# phy_pcs_cmn_registers: IP-XACT component
VLNV cadence:cdns_lib:phy_pcs_cmn_registers:1685-2009

## Address spaces and blocks
sd3101_t4_registers.sd3101_phy_registers: base 0x30000, range 0x3ff, width 32

## Registers
Registers are 32-bit, read-write, reset 0x0 unless marked. A register's access mark holds for its fields unless they carry their own. Offsets are from the block's base; lines under a group give offsets from that group; [hi:lo] are bit positions; {n}, {i} and the like mark numbered series; 'fields as' and 'values as' point back to an identical list; <NAME> marks a mode.

## sd3101_t4_registers.sd3101_phy_registers
Base 0x00030000
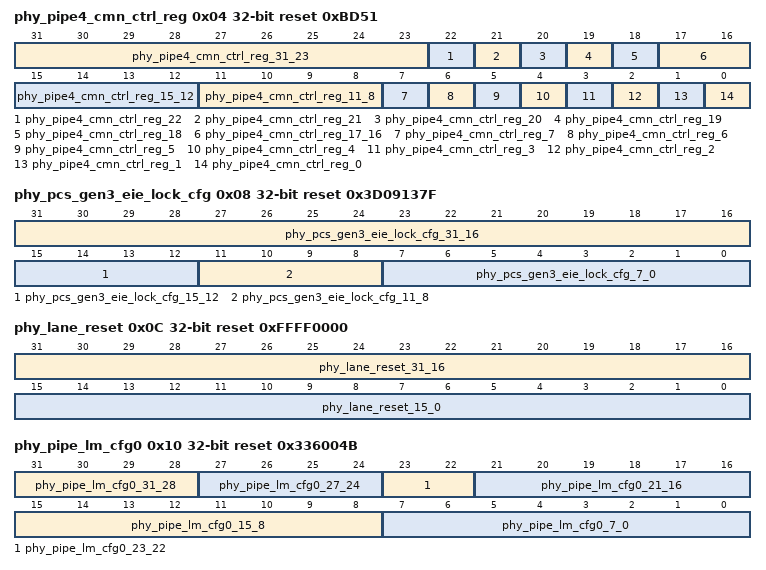
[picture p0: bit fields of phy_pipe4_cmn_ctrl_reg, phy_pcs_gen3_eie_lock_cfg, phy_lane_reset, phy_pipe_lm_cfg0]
0x04 phy_pipe4_cmn_ctrl_reg reset 0xBD51 — PIPE4 common control register
  [31:23] phy_pipe4_cmn_ctrl_reg_31_23 ro — RSVD3
  [22] phy_pipe4_cmn_ctrl_reg_22 — 128B_EIOS_CLR_CAL
  [21] phy_pipe4_cmn_ctrl_reg_21 — 128B_IGNORE_SIGDET
  [20] phy_pipe4_cmn_ctrl_reg_20 — 8B10B_IGNORE_SIGDET
  [19] phy_pipe4_cmn_ctrl_reg_19 — EIOS_CYC_ERR_MSK
  [18] phy_pipe4_cmn_ctrl_reg_18 — EIOS_CLR_CAL
  [17:16] phy_pipe4_cmn_ctrl_reg_17_16 — SIGDET_DEL
  [15:12] phy_pipe4_cmn_ctrl_reg_15_12 — USB_SS_LFPS_STRETCH
  [11:8] phy_pipe4_cmn_ctrl_reg_11_8 — USB_SSPLUS_LFPS_STRETCH
  [7] phy_pipe4_cmn_ctrl_reg_7 ro — RSVD2
  [6] phy_pipe4_cmn_ctrl_reg_6 — TX_ELEC_IDLE_PRE_REL
  [5] phy_pipe4_cmn_ctrl_reg_5 ro — RSVD1
  [4] phy_pipe4_cmn_ctrl_reg_4 — CAL_REALIGN
  [3] phy_pipe4_cmn_ctrl_reg_3 — USB_ERR_COR_DISABLE
  [2] phy_pipe4_cmn_ctrl_reg_2 — USB_PIPE3_SKIP_COMP_EN
  [1] phy_pipe4_cmn_ctrl_reg_1 — USB_LPBKSLV_EC_DISABLE
  [0] phy_pipe4_cmn_ctrl_reg_0 — USB_EB_REALIGN_EN
0x08 phy_pcs_gen3_eie_lock_cfg reset 0x3D09137F — PHY PCS Gen3 EIE lock configuration register
  [31:16] phy_pcs_gen3_eie_lock_cfg_31_16 — RCV_DET_INH
  [15:12] phy_pcs_gen3_eie_lock_cfg_15_12 — EIE_FAST_LOCK_CNT
  [11:8] phy_pcs_gen3_eie_lock_cfg_11_8 — EIE_LOCK_CNT
  [7:0] phy_pcs_gen3_eie_lock_cfg_7_0 — EIE_FULL_LOCK_CNT
0x0C phy_lane_reset reset 0xFFFF0000
  [31:16] phy_lane_reset_31_16 — CDB_RST
  [15:0] phy_lane_reset_15_0 ro — RSVD
0x10 phy_pipe_lm_cfg0 reset 0x336004B — PIPE lane margining configuration 0 register
  [31:28] phy_pipe_lm_cfg0_31_28 ro — RSVD2
  [27:24] phy_pipe_lm_cfg0_27_24 — WAIT_TIME
  [23:22] phy_pipe_lm_cfg0_23_22 ro — RSVD1
  [21:16] phy_pipe_lm_cfg0_21_16 — SMPL_CNT
  [15:8] phy_pipe_lm_cfg0_15_8 ro — RSVD0
  [7:0] phy_pipe_lm_cfg0_7_0 — CFG
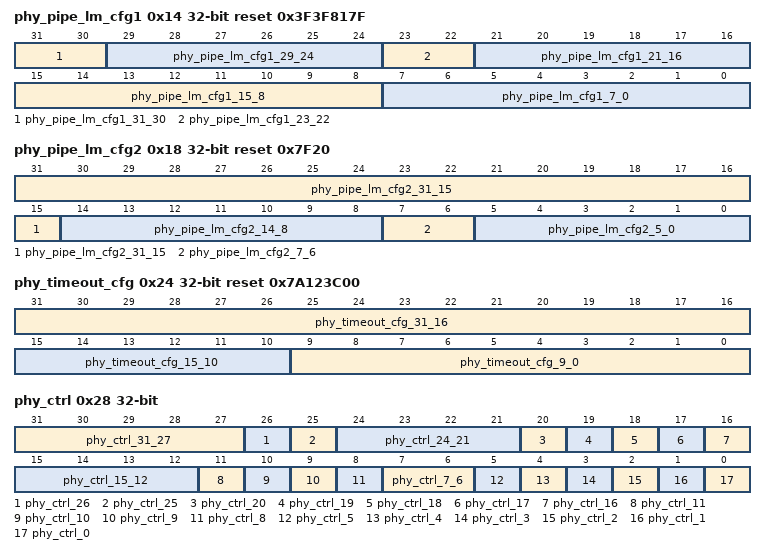
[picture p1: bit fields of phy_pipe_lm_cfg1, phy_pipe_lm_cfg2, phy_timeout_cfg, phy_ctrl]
0x14 phy_pipe_lm_cfg1 reset 0x3F3F817F — PIPE lane margining configuration 1 register
  [31:30] phy_pipe_lm_cfg1_31_30 ro — RSVD1
  [29:24] phy_pipe_lm_cfg1_29_24 — ERR_CNT_THR
  [23:22] phy_pipe_lm_cfg1_23_22 ro — RSVD0
  [21:16] phy_pipe_lm_cfg1_21_16 — ERR_CNT_MAX
  [15:8] phy_pipe_lm_cfg1_15_8 — SMP_CNT_THR
  [7:0] phy_pipe_lm_cfg1_7_0 — SMP_CNT_MAX
0x18 phy_pipe_lm_cfg2 reset 0x7F20 — PIPE lane margining configuration 2 register
  [31:15] phy_pipe_lm_cfg2_31_15 ro — RSVD1
  [14:8] phy_pipe_lm_cfg2_14_8 — VOLT_OFFSET
  [7:6] phy_pipe_lm_cfg2_7_6 ro — RSVD0
  [5:0] phy_pipe_lm_cfg2_5_0 — TIME_OFFSET
0x24 phy_timeout_cfg reset 0x7A123C00 — PHY timeout configuration register
  [31:16] phy_timeout_cfg_31_16 — ST_CHG_TO
  [15:10] phy_timeout_cfg_15_10 — L1_X_EXIT_FAST_CNT
  [9:0] phy_timeout_cfg_9_0 ro — RSVD
0x28 phy_ctrl — PHY common control and status register
  [31:27] phy_ctrl_31_27 ro — RSVD
  [26] phy_ctrl_26 ro — typec_conn_dir_cdb
  [25] phy_ctrl_25 ro — RSVD
  [24:21] phy_ctrl_24_21 ro — phy_mode_cdb
  [20] phy_ctrl_20 ro — PIPE4_RESET_N
  [19] phy_ctrl_19 ro — PIPE7_RESET_N
  [18] phy_ctrl_18 ro — DP_RESET_N
  [17] phy_ctrl_17 write-1-clears — APB_MSTR_PERR
  [16] phy_ctrl_16 write-1-clears — CDB_PERROR_PHY
  [15:12] phy_ctrl_15_12 ro — RSVD4
  [11] phy_ctrl_11 — PERR_FLAG
  [10] phy_ctrl_10 ro — RSVD3
  [9] phy_ctrl_9 ro — MAX_PCLK_ACK
  [8] phy_ctrl_8 ro — MAX_PCLK_REQ
  [7:6] phy_ctrl_7_6 ro — RSVD3
  [5] phy_ctrl_5 write-1-clears — PLL_OK
  [4] phy_ctrl_4 ro — PIPE7_PLL0_EN
  [3] phy_ctrl_3 ro — RSVD2
  [2] phy_ctrl_2 ro — RSVD1
  [1] phy_ctrl_1 ro — PHY_RESET_N
  [0] phy_ctrl_0 write-1-clears — UC_INIT_COMPLETE
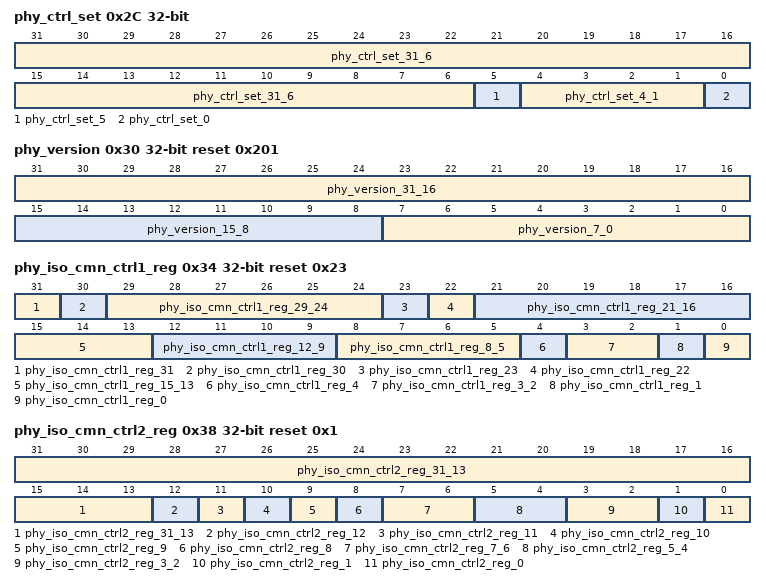
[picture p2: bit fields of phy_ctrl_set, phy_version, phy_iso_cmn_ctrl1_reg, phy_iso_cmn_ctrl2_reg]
0x2C phy_ctrl_set — PHY control and status set register
  [31:6] phy_ctrl_set_31_6 ro — RSVD
  [5] phy_ctrl_set_5 write-1-sets — SET5
  [4:1] phy_ctrl_set_4_1 ro — RSVD
  [0] phy_ctrl_set_0 write-1-sets — SET0
0x30 phy_version reset 0x201
  [31:16] phy_version_31_16 ro — RSVD
  [15:8] phy_version_15_8 ro — MAJOR_REV
  [7:0] phy_version_7_0 ro — MINOR_REV
0x34 phy_iso_cmn_ctrl1_reg reset 0x23 — PHY ISO common control 1 register
  [31] phy_iso_cmn_ctrl1_reg_31 ro — PMA_XCVR_PLLCLK_EN_ACK
  [30] phy_iso_cmn_ctrl1_reg_30 — tx_lfps_mode
  [29:24] phy_iso_cmn_ctrl1_reg_29_24 ro — xcvr_power_state_ack
  [23] phy_iso_cmn_ctrl1_reg_23 — PLLCLK_EN
  [22] phy_iso_cmn_ctrl1_reg_22 — tx_lfps_en
  [21:16] phy_iso_cmn_ctrl1_reg_21_16 — ISO_CMN_CTRL1_BITS
  [15:13] phy_iso_cmn_ctrl1_reg_15_13 — xcvr_data_width_ln
  [12:9] phy_iso_cmn_ctrl1_reg_12_9 ro — RSVD
  [8:5] phy_iso_cmn_ctrl1_reg_8_5 — PHY_MODE
  [4] phy_iso_cmn_ctrl1_reg_4 — TYPEC_CONN_DIR
  [3:2] phy_iso_cmn_ctrl1_reg_3_2 ro — RSVD
  [1] phy_iso_cmn_ctrl1_reg_1 — DP_RST_N
  [0] phy_iso_cmn_ctrl1_reg_0 — PHY_RST_N
0x38 phy_iso_cmn_ctrl2_reg reset 0x1 — PHY ISO common control 2 register
  [31:13] phy_iso_cmn_ctrl2_reg_31_13 ro — RSVD
  [12] phy_iso_cmn_ctrl2_reg_12 — PIPE4_EB_MODE
  [11] phy_iso_cmn_ctrl2_reg_11 ro — RSVD
  [10] phy_iso_cmn_ctrl2_reg_10 — PIPE4_32BIT_SEL
  [9] phy_iso_cmn_ctrl2_reg_9 ro — RSVD
  [8] phy_iso_cmn_ctrl2_reg_8 — PIPE4_RATE
  [7:6] phy_iso_cmn_ctrl2_reg_7_6 ro — RSVD
  [5:4] phy_iso_cmn_ctrl2_reg_5_4 — PIPE4_PWRDWN
  [3:2] phy_iso_cmn_ctrl2_reg_3_2 ro — RSVD
  [1] phy_iso_cmn_ctrl2_reg_1 ro — RSVD
  [0] phy_iso_cmn_ctrl2_reg_0 — PIPE4_RST_N
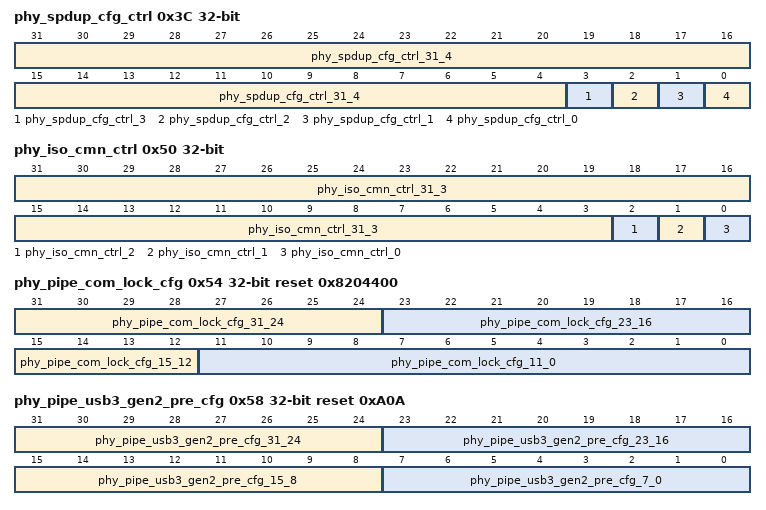
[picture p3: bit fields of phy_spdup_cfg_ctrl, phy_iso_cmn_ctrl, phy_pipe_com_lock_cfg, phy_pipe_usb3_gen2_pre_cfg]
0x3C phy_spdup_cfg_ctrl — PHY speedup configuration and control register
  [31:4] phy_spdup_cfg_ctrl_31_4 ro — RSVD1
  [3] phy_spdup_cfg_ctrl_3 ro — SPDUP_CMPL
  [2] phy_spdup_cfg_ctrl_2 — SPDUP_STALL
  [1] phy_spdup_cfg_ctrl_1 — SPDUP_EN
  [0] phy_spdup_cfg_ctrl_0 ro — RSVD0
0x50 phy_iso_cmn_ctrl — PHY common control signal isolation register
  [31:3] phy_iso_cmn_ctrl_31_3 ro — RSVD
  [2] phy_iso_cmn_ctrl_2 — PLL_EN
  [1] phy_iso_cmn_ctrl_1 — CLK_MAX_REQ
  [0] phy_iso_cmn_ctrl_0 ro — RSVD0
0x54 phy_pipe_com_lock_cfg reset 0x8204400 — PHY PIPE common lock configuration register
  [31:24] phy_pipe_com_lock_cfg_31_24 — COM_FAST_LOCK_CNT
  [23:16] phy_pipe_com_lock_cfg_23_16 — COM_LOCK_CNT
  [15:12] phy_pipe_com_lock_cfg_15_12 — CAL_UNLOCK_CNT
  [11:0] phy_pipe_com_lock_cfg_11_0 — COM_FULL_LOCK_CNT
0x58 phy_pipe_usb3_gen2_pre_cfg reset 0xA0A — PHY USB3 Gen 2 pre-shoot configuration register
  [31:24] phy_pipe_usb3_gen2_pre_cfg_31_24 — COM_FAST_LOCK_CNT
  [23:16] phy_pipe_usb3_gen2_pre_cfg_23_16 — COM_LOCK_CNT
  [15:8] phy_pipe_usb3_gen2_pre_cfg_15_8 — CAL_UNLOCK_CNT
  [7:0] phy_pipe_usb3_gen2_pre_cfg_7_0 — COM_FULL_LOCK_CNT
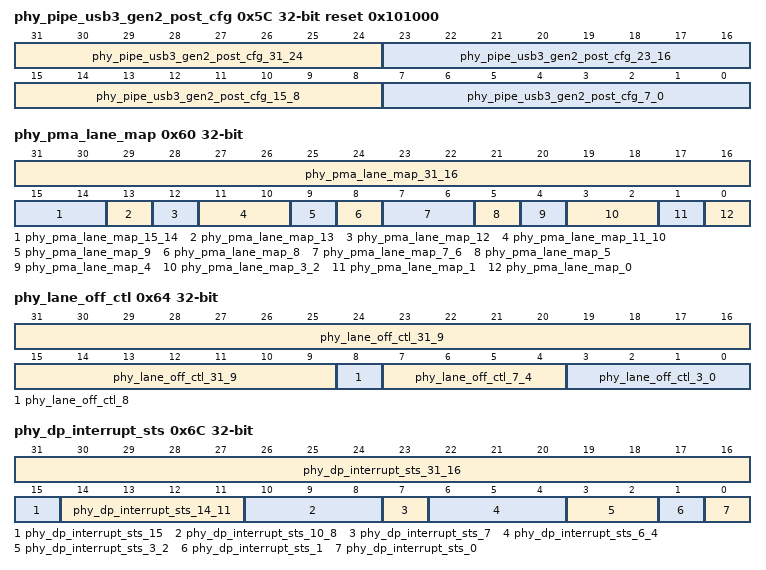
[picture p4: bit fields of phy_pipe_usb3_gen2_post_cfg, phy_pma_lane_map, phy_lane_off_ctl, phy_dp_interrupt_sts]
0x5C phy_pipe_usb3_gen2_post_cfg reset 0x101000 — PHY USB3 Gen 2 pre-shoot configuration register
  [31:24] phy_pipe_usb3_gen2_post_cfg_31_24 — COM_FAST_LOCK_CNT
  [23:16] phy_pipe_usb3_gen2_post_cfg_23_16 — COM_LOCK_CNT
  [15:8] phy_pipe_usb3_gen2_post_cfg_15_8 — CAL_UNLOCK_CNT
  [7:0] phy_pipe_usb3_gen2_post_cfg_7_0 — COM_FULL_LOCK_CNT
0x60 phy_pma_lane_map — PHY/PMA Lane Mapping Register
  [31:16] phy_pma_lane_map_31_16 ro — RSVD
  [15:14] phy_pma_lane_map_15_14 — PMA_L3_MAP
  [13] phy_pma_lane_map_13 ro — RSVD
  [12] phy_pma_lane_map_12 — PMA_L3_SEL
  [11:10] phy_pma_lane_map_11_10 — PMA_L2_MAP
  [9] phy_pma_lane_map_9 ro — RSVD
  [8] phy_pma_lane_map_8 — PMA_L2_SEL
  [7:6] phy_pma_lane_map_7_6 — PMA_L1_MAP
  [5] phy_pma_lane_map_5 ro — RSVD
  [4] phy_pma_lane_map_4 — PMA_L1_SEL
  [3:2] phy_pma_lane_map_3_2 — PMA_L0_MAP
  [1] phy_pma_lane_map_1 ro — RSVD
  [0] phy_pma_lane_map_0 — PMA_L0_SEL
0x64 phy_lane_off_ctl — PHY Lane Off control register
  [31:9] phy_lane_off_ctl_31_9 ro — RSVD
  [8] phy_lane_off_ctl_8 — USB_LANE_DISABLE
  [7:4] phy_lane_off_ctl_7_4 ro — RSVD
  [3:0] phy_lane_off_ctl_3_0 — DP_LANE_DISABLE
0x6C phy_dp_interrupt_sts — PHY DP state change status register
  [31:16] phy_dp_interrupt_sts_31_16 ro — RSVD
  [15] phy_dp_interrupt_sts_15 — STATE_CHANGE_MON_EN
  [14:11] phy_dp_interrupt_sts_14_11 ro — RSVD
  [10:8] phy_dp_interrupt_sts_10_8 ro — NEXT_STATE
  [7] phy_dp_interrupt_sts_7 ro — RSVD
  [6:4] phy_dp_interrupt_sts_6_4 ro — CURRENT_STATE
  [3:2] phy_dp_interrupt_sts_3_2 ro — RSVD
  [1] phy_dp_interrupt_sts_1 read-clears — RATE_CHANGE_STS
  [0] phy_dp_interrupt_sts_0 read-clears — PWR_CHANGE_STS
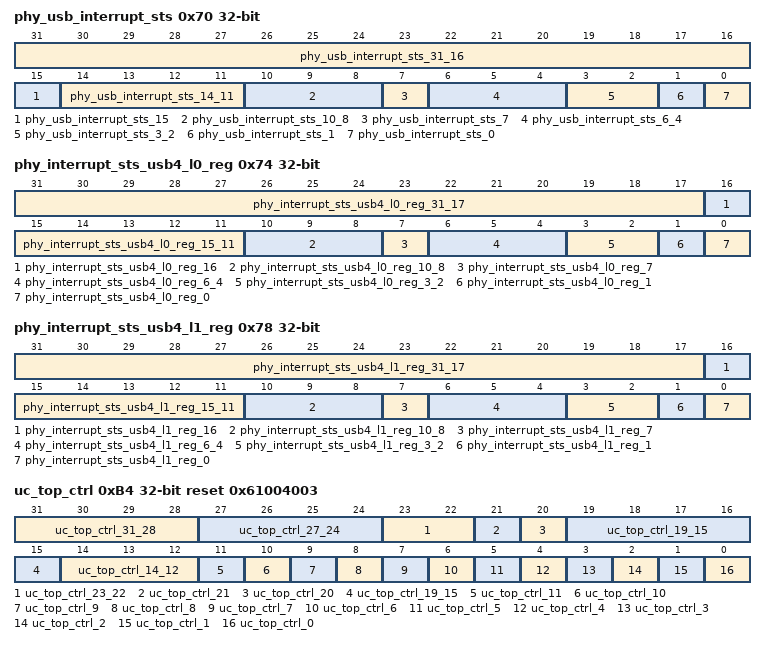
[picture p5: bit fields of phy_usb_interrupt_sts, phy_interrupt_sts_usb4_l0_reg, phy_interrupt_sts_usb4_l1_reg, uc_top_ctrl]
0x70 phy_usb_interrupt_sts — PHY USB3 state change status register
  [31:16] phy_usb_interrupt_sts_31_16 ro — RSVD
  [15] phy_usb_interrupt_sts_15 — STATE_CHANGE_MON_EN
  [14:11] phy_usb_interrupt_sts_14_11 ro — RSVD
  [10:8] phy_usb_interrupt_sts_10_8 ro — NEXT_STATE
  [7] phy_usb_interrupt_sts_7 ro — RSVD
  [6:4] phy_usb_interrupt_sts_6_4 ro — CURRENT_STATE
  [3:2] phy_usb_interrupt_sts_3_2 ro — RSVD
  [1] phy_usb_interrupt_sts_1 read-clears — RATE_CHANGE_STS
  [0] phy_usb_interrupt_sts_0 read-clears — PWR_CHANGE_STS
0x74 phy_interrupt_sts_usb4_l0_reg — PHY USB4 L0 state change status register
  [31:17] phy_interrupt_sts_usb4_l0_reg_31_17 ro — RSVD
  [16] phy_interrupt_sts_usb4_l0_reg_16 — STATE_CHG_MONITOR_EN
  [15:11] phy_interrupt_sts_usb4_l0_reg_15_11 ro — RSVD2
  [10:8] phy_interrupt_sts_usb4_l0_reg_10_8 ro — REQ_PWRST_RATE
  [7] phy_interrupt_sts_usb4_l0_reg_7 ro — RSVD3
  [6:4] phy_interrupt_sts_usb4_l0_reg_6_4 ro — CUR_PWRST_RATE
  [3:2] phy_interrupt_sts_usb4_l0_reg_3_2 ro — RSVD
  [1] phy_interrupt_sts_usb4_l0_reg_1 write-1-clears — RATE_CHG_TIMEOUT
  [0] phy_interrupt_sts_usb4_l0_reg_0 write-1-clears — PWRST_CHG_TIMEOUT
0x78 phy_interrupt_sts_usb4_l1_reg — PHY USB4 L1 state change status register
  [31:17] phy_interrupt_sts_usb4_l1_reg_31_17 ro — RSVD
  [16] phy_interrupt_sts_usb4_l1_reg_16 — STATE_CHG_MONITOR_EN
  [15:11] phy_interrupt_sts_usb4_l1_reg_15_11 ro — RSVD2
  [10:8] phy_interrupt_sts_usb4_l1_reg_10_8 ro — REQ_PWRST_RATE
  [7] phy_interrupt_sts_usb4_l1_reg_7 ro — RSVD3
  [6:4] phy_interrupt_sts_usb4_l1_reg_6_4 ro — CUR_PWRST_RATE
  [3:2] phy_interrupt_sts_usb4_l1_reg_3_2 ro — RSVD4
  [1] phy_interrupt_sts_usb4_l1_reg_1 write-1-clears — RATE_CHG_TIMEOUT
  [0] phy_interrupt_sts_usb4_l1_reg_0 write-1-clears — PWRST_CHG_TIMEOUT
0x7C uc_top_scrpad15 — PHY top uController scratchpad/mailbox 15 register
  [31:0] uc_top_scrpad15_31_0 — VALUE
0xB4 uc_top_ctrl reset 0x61004003 — PHY top uController control register
  [31:28] uc_top_ctrl_31_28 — SRAM_PD_OUT
  [27:24] uc_top_ctrl_27_24 — SRAM_PD_IN
  [23:22] uc_top_ctrl_23_22 — SRAM_PD_MIN
  [21] uc_top_ctrl_21 — SRAM_PD_OVR
  [20] uc_top_ctrl_20 — SRAM_PD_CLK
  [19:15] uc_top_ctrl_19_15 ro — RSVD2
  [14:12] uc_top_ctrl_14_12 — IRAM_BASE
  [11] uc_top_ctrl_11 — AUTO_INC_DIS
  [10] uc_top_ctrl_10 ro — RSVD1
  [9] uc_top_ctrl_9 ro — SRAM_INIT_DN
  [8] uc_top_ctrl_8 — SRAM_INIT
  [7] uc_top_ctrl_7 ro — PWAITMODE
  [6] uc_top_ctrl_6 — CDB_CLK_GATE
  [5] uc_top_ctrl_5 — CDB_RESYNC
  [4] uc_top_ctrl_4 — ECC_EN
  [3] uc_top_ctrl_3 ro — RSVD0
  [2] uc_top_ctrl_2 wo — SELF_RST
  [1] uc_top_ctrl_1 — SOFT_RST
  [0] uc_top_ctrl_0 — STALL
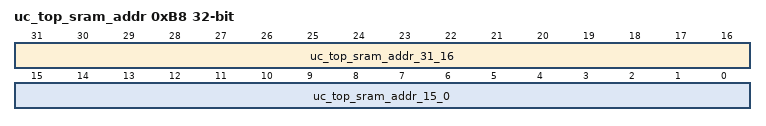
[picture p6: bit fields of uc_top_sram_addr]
0xB8 uc_top_sram_addr — PHY top uController SRAM address register
  [31:16] uc_top_sram_addr_31_16 ro — RSVD
  [15:0] uc_top_sram_addr_15_0 — ADDRESS
{0xBC+4i} uc_top_scrpad{i} (i=0..7) — PHY top uController scratchpad/mailbox {i} register
  [31:0] uc_top_scrpad{i}_31_0 — VALUE
0xDC phy_apb_mstr_addr — PHY APB master address register
  [31:0] phy_apb_mstr_addr_31_0 — ADDRESS
0x100 uc_top_sram_access — PHY lane uController SRAM access register
  [31:0] uc_top_sram_access_31_0 — ACCESS
